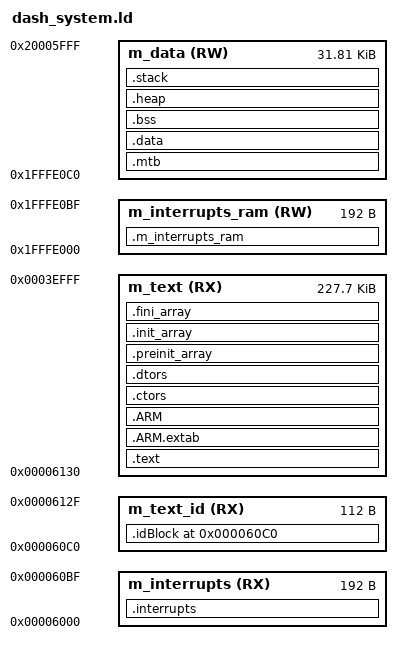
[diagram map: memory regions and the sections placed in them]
/*
  dash_system.ld - Linker commands for use with bootloader on Hologram Dash.

  https://hologram.io

  Copyright (c) 2017 Konekt, Inc.  All rights reserved.

  This library is free software; you can redistribute it and/or
  modify it under the terms of the GNU Lesser General Public
  License as published by the Free Software Foundation; either
  version 2.1 of the License, or (at your option) any later version.

  This library is distributed in the hope that it will be useful,
  but WITHOUT ANY WARRANTY; without even the implied warranty of
  MERCHANTABILITY or FITNESS FOR A PARTICULAR PURPOSE.  See the GNU
  Lesser General Public License for more details.

  You should have received a copy of the GNU Lesser General Public
  License along with this library; if not, write to the Free Software
  Foundation, Inc., 51 Franklin St, Fifth Floor, Boston, MA  02110-1301  USA
*/
/* Entry Point */
ENTRY(Reset_Handler)

HEAP_SIZE  = DEFINED(__heap_size__)  ? __heap_size__  : 0x1000;
STACK_SIZE = DEFINED(__stack_size__) ? __stack_size__ : 0x1000;
/* Specify the memory areas */
MEMORY {
 /* m_reserved            (R)   : ORIGIN = 0x00000000, LENGTH = 0x00006000 */
  m_interrupts          (RX)  : ORIGIN = 0x00006000, LENGTH = 0x000000C0
  m_text_id             (RX)  : ORIGIN = 0x000060C0, LENGTH = 0x00000070
  m_interrupts_ram      (RW)  : ORIGIN = 0x1FFFE000, LENGTH = 0x000000C0
  m_text                (RX)  : ORIGIN = 0x00006130, LENGTH = 0x00038ED0 /*for 256KB part*/
  m_data                (RW)  : ORIGIN = 0x1FFFE0C0, LENGTH = 0x00007F40
}

/* Define output sections */
SECTIONS
{
  /* The startup code goes first into INTERNAL_FLASH */
  .interrupts :
  {
    __VECTOR_TABLE = .;
    . = ALIGN(4);
    KEEP(*(.isr_vector))     /* Startup code */
    . = ALIGN(4);
  } > m_interrupts

  __VECTOR_RAM = ORIGIN(m_interrupts_ram);

  /*
  .reserved :
  {
    . = ALIGN(4);
    KEEP(*(.Reserved))
    . = ALIGN(4);
  } > m_reserved
  */

  /* placing my named section at given address: */
  .idBlock 0x000060C0 :
  {
    KEEP(*(.idSection)) /* keep my variable even if not referenced */
  } > m_text_id

  /* The program code and other data goes into INTERNAL_FLASH */
  .text :
  {
    . = ALIGN(4);
    *(.text)                 /* .text sections (code) */
    *(.text*)                /* .text* sections (code) */
    *(.rodata)               /* .rodata sections (constants, strings, etc.) */
    *(.rodata*)              /* .rodata* sections (constants, strings, etc.) */
    *(.glue_7)               /* glue arm to thumb code */
    *(.glue_7t)              /* glue thumb to arm code */
    *(.eh_frame)
    KEEP (*(.init))
    KEEP (*(.fini))
    . = ALIGN(4);
  } > m_text

  .ARM.extab :
  {
    *(.ARM.extab* .gnu.linkonce.armextab.*)
  } > m_text

  .ARM :
  {
    __exidx_start = .;
    *(.ARM.exidx*)
    __exidx_end = .;
  } > m_text

 .ctors :
  {
    __CTOR_LIST__ = .;
    /* gcc uses crtbegin.o to find the start of
       the constructors, so we make sure it is
       first.  Because this is a wildcard, it
       doesn't matter if the user does not
       actually link against crtbegin.o; the
       linker won't look for a file to match a
       wildcard.  The wildcard also means that it
       doesn't matter which directory crtbegin.o
       is in.  */
    KEEP (*crtbegin.o(.ctors))
    KEEP (*crtbegin?.o(.ctors))
    /* We don't want to include the .ctor section from
       from the crtend.o file until after the sorted ctors.
       The .ctor section from the crtend file contains the
       end of ctors marker and it must be last */
    KEEP (*(EXCLUDE_FILE(*crtend?.o *crtend.o) .ctors))
    KEEP (*(SORT(.ctors.*)))
    KEEP (*(.ctors))
    __CTOR_END__ = .;
  } > m_text

  .dtors :
  {
    __DTOR_LIST__ = .;
    KEEP (*crtbegin.o(.dtors))
    KEEP (*crtbegin?.o(.dtors))
    KEEP (*(EXCLUDE_FILE(*crtend?.o *crtend.o) .dtors))
    KEEP (*(SORT(.dtors.*)))
    KEEP (*(.dtors))
    __DTOR_END__ = .;
  } > m_text

  .preinit_array :
  {
    PROVIDE_HIDDEN (__preinit_array_start = .);
    KEEP (*(.preinit_array*))
    PROVIDE_HIDDEN (__preinit_array_end = .);
  } > m_text

  .init_array :
  {
    PROVIDE_HIDDEN (__init_array_start = .);
    KEEP (*(SORT(.init_array.*)))
    KEEP (*(.init_array*))
    PROVIDE_HIDDEN (__init_array_end = .);
  } > m_text

  .fini_array :
  {
    PROVIDE_HIDDEN (__fini_array_start = .);
    KEEP (*(SORT(.fini_array.*)))
    KEEP (*(.fini_array*))
    PROVIDE_HIDDEN (__fini_array_end = .);
  } > m_text

  __etext = .;    /* define a global symbol at end of code */
  __DATA_ROM = .; /* Symbol is used by startup for data initialization */

  /* reserve MTB memory at the beginning of m_data */
  .mtb : /* MTB buffer address as defined by the hardware */
  {
    . = ALIGN(8);
    _mtb_start = .;
    KEEP(*(.mtb_buf)) /* need to KEEP Micro Trace Buffer as not referenced by application */
    . = ALIGN(8);
    _mtb_end = .;
  } > m_data

  .data : AT(__DATA_ROM)
  {
    . = ALIGN(4);
    __DATA_RAM = .;
    __data_start__ = .;      /* create a global symbol at data start */
    *(.data)                 /* .data sections */
    *(.data*)                /* .data* sections */
    KEEP(*(.jcr*))
    . = ALIGN(4);
    __data_end__ = .;        /* define a global symbol at data end */
  } > m_data

  /* Symbol is used by startup for data initialization */
  __DATA_END = __DATA_ROM + (__data_end__ - __data_start__);

  __m_interrupts_ram_ROMStart = __DATA_ROM + SIZEOF(.data);
  .m_interrupts_ram : AT(__m_interrupts_ram_ROMStart)
  {
     . = ALIGN(4);
     __m_interrupts_ram_RAMStart = .;
     *(.m_interrupts_ram)    /* This is an User defined section */
    . += 0x00C0;
     __m_interrupts_ram_RAMEnd = .;
     . = ALIGN(4);
  } > m_interrupts_ram
  __m_interrupts_ram_ROMSize = __m_interrupts_ram_RAMEnd - __m_interrupts_ram_RAMStart;
  __RAM_VECTOR_TABLE_SIZE_BYTES = __m_interrupts_ram_RAMEnd - __m_interrupts_ram_RAMStart;
  /* Uninitialized data section */
  .bss :
  {
    /* This is used by the startup in order to initialize the .bss section */
    . = ALIGN(4);
    __START_BSS = .;
    __bss_start__ = .;
    *(.bss)
    *(.bss*)
    *(COMMON)
    . = ALIGN(4);
    __bss_end__ = .;
    __END_BSS = .;
  } > m_data

  .heap :
  {
    . = ALIGN(8);
    __end__ = .;
    PROVIDE(end = .);
    __HeapBase = .;
    . += HEAP_SIZE;
    __HeapLimit = .;
  } > m_data

  .stack :
  {
    . = ALIGN(8);
    . += STACK_SIZE;
  } > m_data

  __StackTop   = ORIGIN(m_data) + LENGTH(m_data);
  __StackLimit = __StackTop - STACK_SIZE;
  PROVIDE(__stack = __StackTop);

  .ARM.attributes 0 : { *(.ARM.attributes) }
}
